# nrf7140_application register map
Vendor: Nordic Semiconductor; Series: nRF71; File version: 1
CPU: CM33 r0p4, little endian, MPU, FPU, 3 interrupt priority bits, 480 interrupts, 8 SAU regions
Registers are 32-bit, read-write, reset 0x0 unless marked. A register's access mark holds for its fields unless they carry their own. Offsets are from the block's base; [hi:lo] are bit positions; lines under a group give offsets from that group; {n}, {i} and the like mark numbered series; 'fields as' and 'values as' point back to an identical list.

## GLOBAL_DISPC_NS (part 3 of 3) — DISPC
Base 0x49004000
0x1000 CORE group — Unspecified
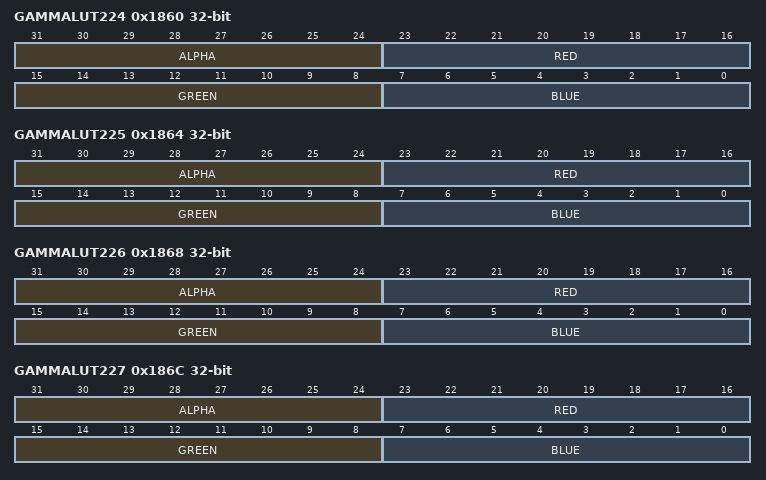
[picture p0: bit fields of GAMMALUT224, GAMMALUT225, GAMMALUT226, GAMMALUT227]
  0x1860 GAMMALUT224 — Layer 2 palette/gamma correction memory region.
    [31:24] ALPHA wo — Color alpha is used as Lut color.
    [23:16] RED wo — Color red is used as Lut color.
    [15:8] GREEN wo — Color green is used as Lut color.
    [7:0] BLUE wo — Color blue is used as Lut color.
  0x1864 GAMMALUT225 — Layer 2 palette/gamma correction memory region.
    fields as CORE.GAMMALUT224
  0x1868 GAMMALUT226 — Layer 2 palette/gamma correction memory region.
    fields as CORE.GAMMALUT224
  0x186C GAMMALUT227 — Layer 2 palette/gamma correction memory region.
    fields as CORE.GAMMALUT224
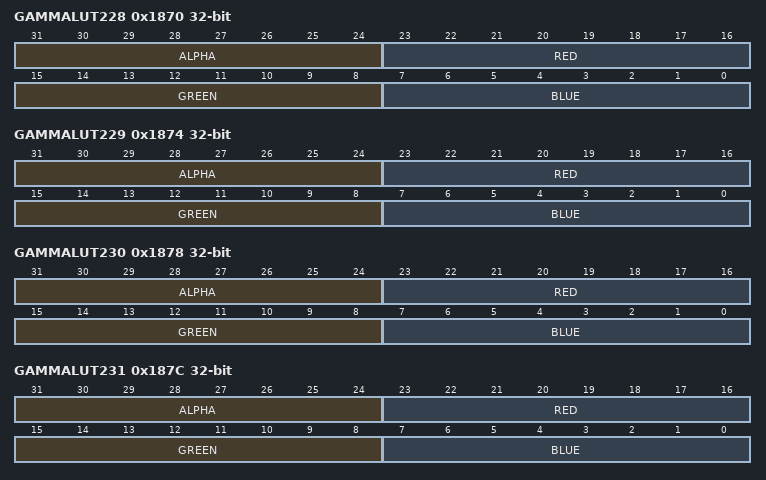
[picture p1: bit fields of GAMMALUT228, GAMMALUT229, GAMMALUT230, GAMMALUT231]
  0x1870 GAMMALUT228 — Layer 2 palette/gamma correction memory region.
    fields as CORE.GAMMALUT224
  0x1874 GAMMALUT229 — Layer 2 palette/gamma correction memory region.
    fields as CORE.GAMMALUT224
  0x1878 GAMMALUT230 — Layer 2 palette/gamma correction memory region.
    fields as CORE.GAMMALUT224
  0x187C GAMMALUT231 — Layer 2 palette/gamma correction memory region.
    fields as CORE.GAMMALUT224
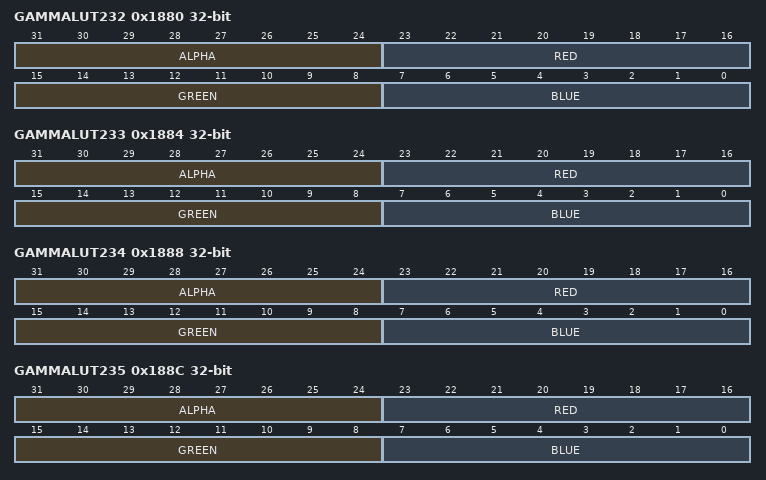
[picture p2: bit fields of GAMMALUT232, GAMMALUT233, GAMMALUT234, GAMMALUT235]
  0x1880 GAMMALUT232 — Layer 2 palette/gamma correction memory region.
    fields as CORE.GAMMALUT224
  0x1884 GAMMALUT233 — Layer 2 palette/gamma correction memory region.
    fields as CORE.GAMMALUT224
  0x1888 GAMMALUT234 — Layer 2 palette/gamma correction memory region.
    fields as CORE.GAMMALUT224
  0x188C GAMMALUT235 — Layer 2 palette/gamma correction memory region.
    fields as CORE.GAMMALUT224
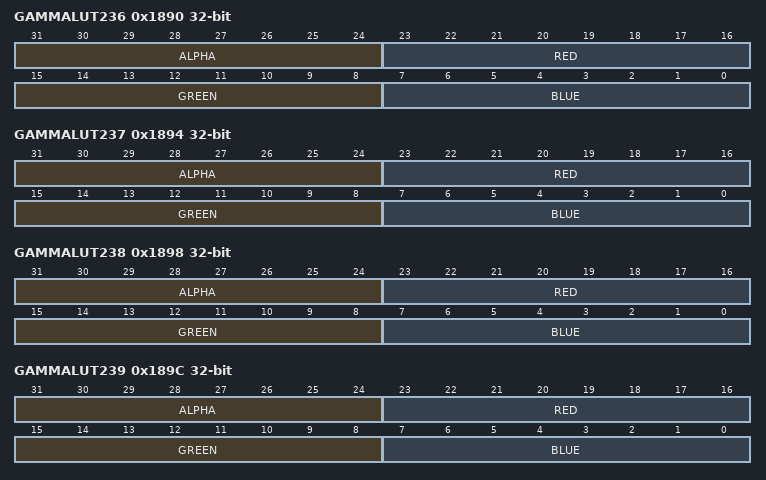
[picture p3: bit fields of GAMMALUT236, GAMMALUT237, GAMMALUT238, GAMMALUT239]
  0x1890 GAMMALUT236 — Layer 2 palette/gamma correction memory region.
    fields as CORE.GAMMALUT224
  0x1894 GAMMALUT237 — Layer 2 palette/gamma correction memory region.
    fields as CORE.GAMMALUT224
  0x1898 GAMMALUT238 — Layer 2 palette/gamma correction memory region.
    fields as CORE.GAMMALUT224
  0x189C GAMMALUT239 — Layer 2 palette/gamma correction memory region.
    fields as CORE.GAMMALUT224
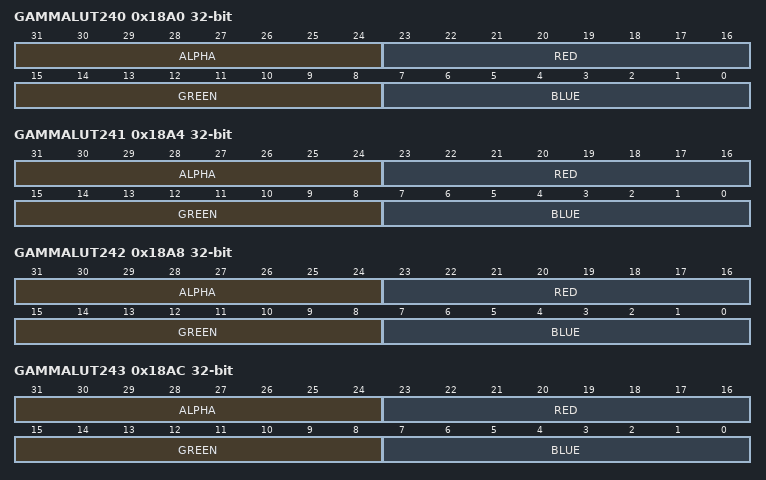
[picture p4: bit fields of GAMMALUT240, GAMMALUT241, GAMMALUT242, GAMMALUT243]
  0x18A0 GAMMALUT240 — Layer 2 palette/gamma correction memory region.
    fields as CORE.GAMMALUT224
  0x18A4 GAMMALUT241 — Layer 2 palette/gamma correction memory region.
    fields as CORE.GAMMALUT224
  0x18A8 GAMMALUT242 — Layer 2 palette/gamma correction memory region.
    fields as CORE.GAMMALUT224
  0x18AC GAMMALUT243 — Layer 2 palette/gamma correction memory region.
    fields as CORE.GAMMALUT224
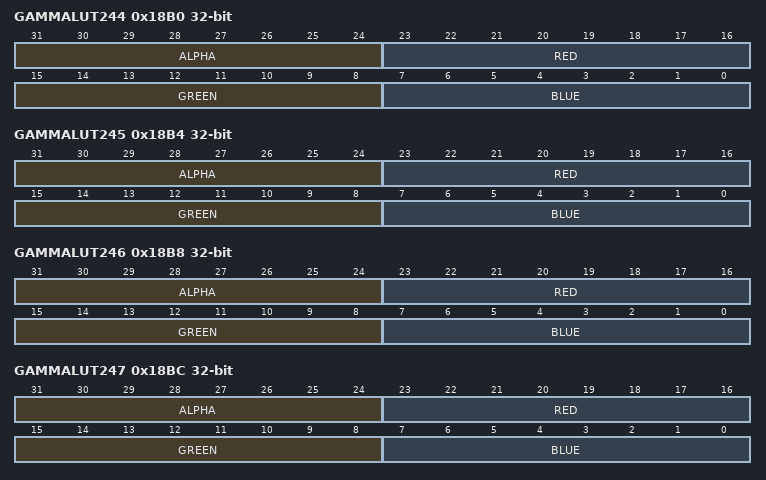
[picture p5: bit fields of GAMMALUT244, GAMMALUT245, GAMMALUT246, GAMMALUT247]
  0x18B0 GAMMALUT244 — Layer 2 palette/gamma correction memory region.
    fields as CORE.GAMMALUT224
  0x18B4 GAMMALUT245 — Layer 2 palette/gamma correction memory region.
    fields as CORE.GAMMALUT224
  0x18B8 GAMMALUT246 — Layer 2 palette/gamma correction memory region.
    fields as CORE.GAMMALUT224
  0x18BC GAMMALUT247 — Layer 2 palette/gamma correction memory region.
    fields as CORE.GAMMALUT224
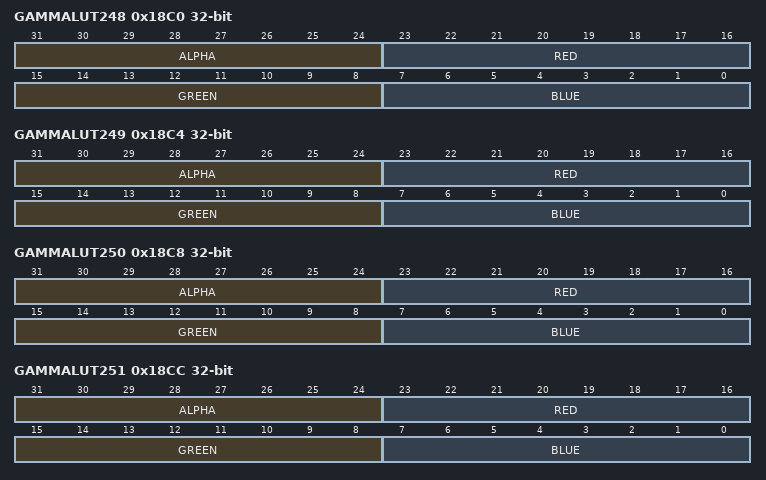
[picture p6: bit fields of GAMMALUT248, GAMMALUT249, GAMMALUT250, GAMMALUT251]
  0x18C0 GAMMALUT248 — Layer 2 palette/gamma correction memory region.
    fields as CORE.GAMMALUT224
  0x18C4 GAMMALUT249 — Layer 2 palette/gamma correction memory region.
    fields as CORE.GAMMALUT224
  0x18C8 GAMMALUT250 — Layer 2 palette/gamma correction memory region.
    fields as CORE.GAMMALUT224
  0x18CC GAMMALUT251 — Layer 2 palette/gamma correction memory region.
    fields as CORE.GAMMALUT224
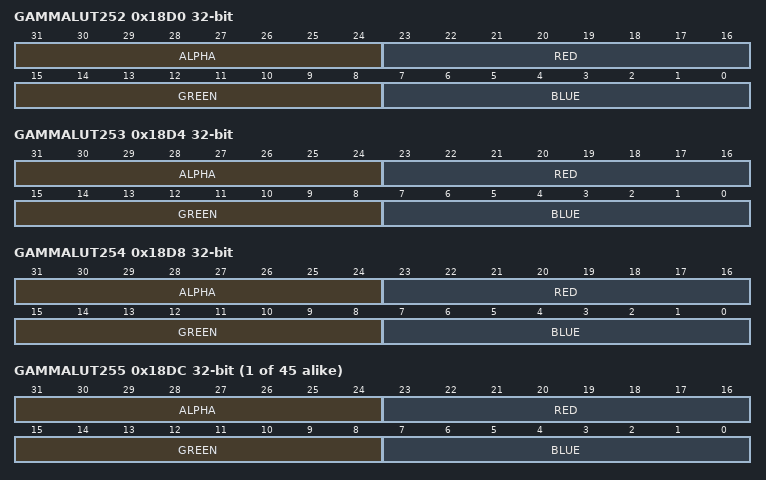
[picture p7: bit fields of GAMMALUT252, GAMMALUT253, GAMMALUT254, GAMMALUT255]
  0x18D0 GAMMALUT252 — Layer 2 palette/gamma correction memory region.
    fields as CORE.GAMMALUT224
  0x18D4 GAMMALUT253 — Layer 2 palette/gamma correction memory region.
    fields as CORE.GAMMALUT224
  0x18D8 GAMMALUT254 — Layer 2 palette/gamma correction memory region.
    fields as CORE.GAMMALUT224
  {0x14E0+4j} GAMMALUT{j} (j=255..299) — Layer 2 palette/gamma correction memory region.
    fields as CORE.GAMMALUT224
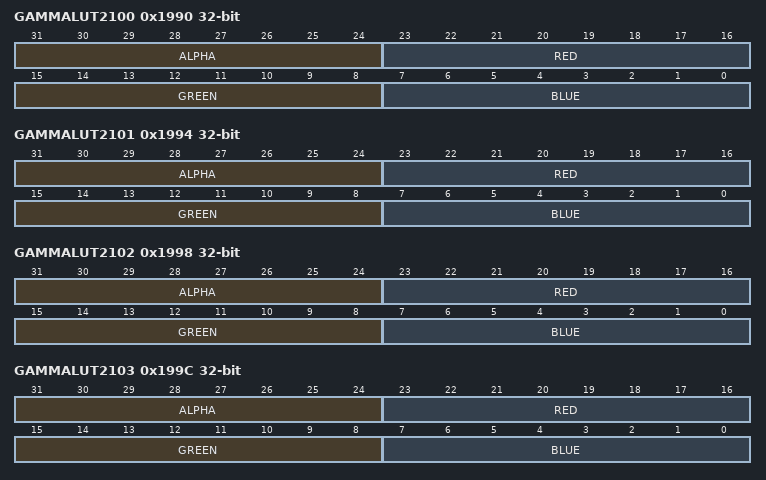
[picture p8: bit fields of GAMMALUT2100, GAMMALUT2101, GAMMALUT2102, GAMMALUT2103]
  0x1990 GAMMALUT2100 — Layer 2 palette/gamma correction memory region.
    fields as CORE.GAMMALUT224
  0x1994 GAMMALUT2101 — Layer 2 palette/gamma correction memory region.
    fields as CORE.GAMMALUT224
  0x1998 GAMMALUT2102 — Layer 2 palette/gamma correction memory region.
    fields as CORE.GAMMALUT224
  0x199C GAMMALUT2103 — Layer 2 palette/gamma correction memory region.
    fields as CORE.GAMMALUT224
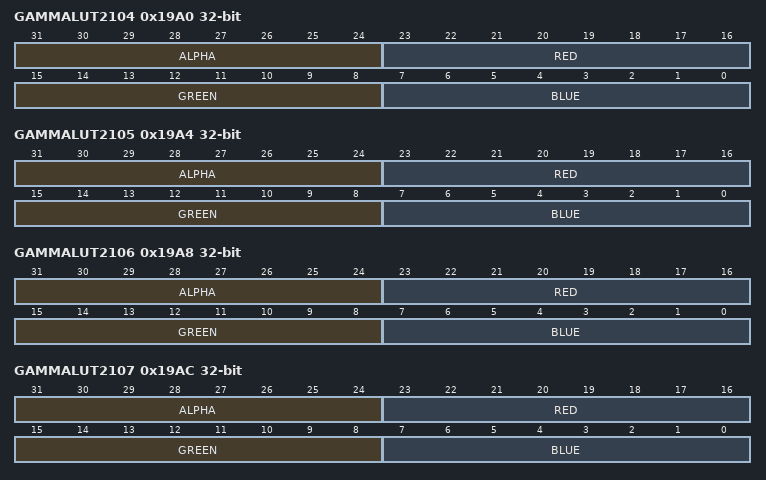
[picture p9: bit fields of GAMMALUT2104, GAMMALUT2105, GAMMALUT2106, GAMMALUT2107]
  0x19A0 GAMMALUT2104 — Layer 2 palette/gamma correction memory region.
    fields as CORE.GAMMALUT224
  0x19A4 GAMMALUT2105 — Layer 2 palette/gamma correction memory region.
    fields as CORE.GAMMALUT224
  0x19A8 GAMMALUT2106 — Layer 2 palette/gamma correction memory region.
    fields as CORE.GAMMALUT224
  0x19AC GAMMALUT2107 — Layer 2 palette/gamma correction memory region.
    fields as CORE.GAMMALUT224
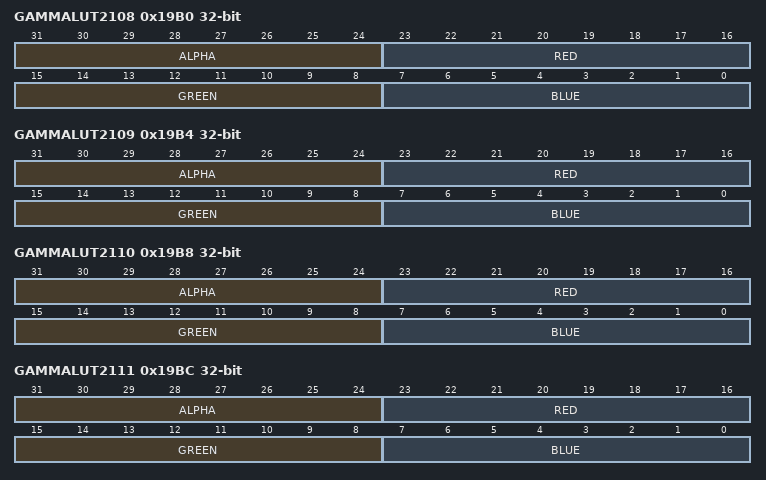
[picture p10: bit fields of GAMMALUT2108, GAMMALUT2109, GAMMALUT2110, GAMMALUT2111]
  0x19B0 GAMMALUT2108 — Layer 2 palette/gamma correction memory region.
    fields as CORE.GAMMALUT224
  0x19B4 GAMMALUT2109 — Layer 2 palette/gamma correction memory region.
    fields as CORE.GAMMALUT224
  0x19B8 GAMMALUT2110 — Layer 2 palette/gamma correction memory region.
    fields as CORE.GAMMALUT224
  0x19BC GAMMALUT2111 — Layer 2 palette/gamma correction memory region.
    fields as CORE.GAMMALUT224
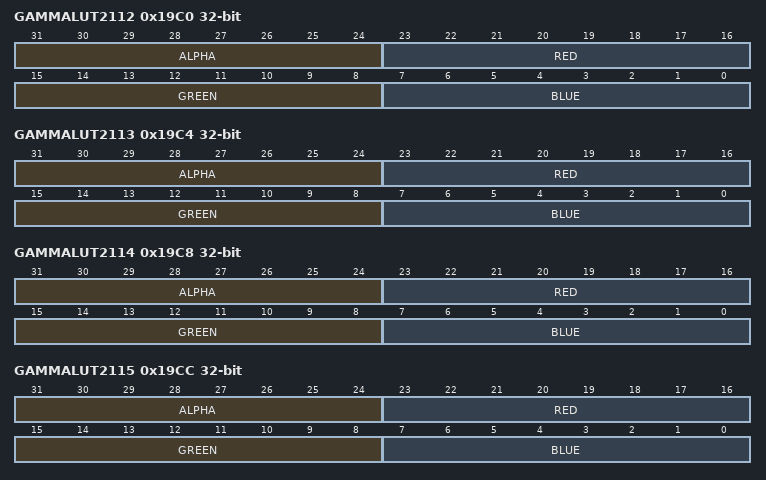
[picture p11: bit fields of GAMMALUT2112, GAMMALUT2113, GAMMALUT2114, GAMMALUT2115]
  0x19C0 GAMMALUT2112 — Layer 2 palette/gamma correction memory region.
    fields as CORE.GAMMALUT224
  0x19C4 GAMMALUT2113 — Layer 2 palette/gamma correction memory region.
    fields as CORE.GAMMALUT224
  0x19C8 GAMMALUT2114 — Layer 2 palette/gamma correction memory region.
    fields as CORE.GAMMALUT224
  0x19CC GAMMALUT2115 — Layer 2 palette/gamma correction memory region.
    fields as CORE.GAMMALUT224
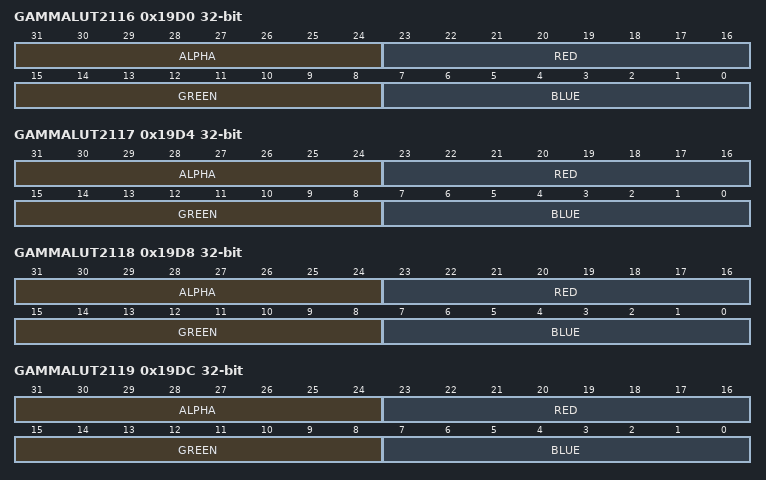
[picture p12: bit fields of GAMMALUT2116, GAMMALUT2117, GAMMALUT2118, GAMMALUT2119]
  0x19D0 GAMMALUT2116 — Layer 2 palette/gamma correction memory region.
    fields as CORE.GAMMALUT224
  0x19D4 GAMMALUT2117 — Layer 2 palette/gamma correction memory region.
    fields as CORE.GAMMALUT224
  0x19D8 GAMMALUT2118 — Layer 2 palette/gamma correction memory region.
    fields as CORE.GAMMALUT224
  0x19DC GAMMALUT2119 — Layer 2 palette/gamma correction memory region.
    fields as CORE.GAMMALUT224
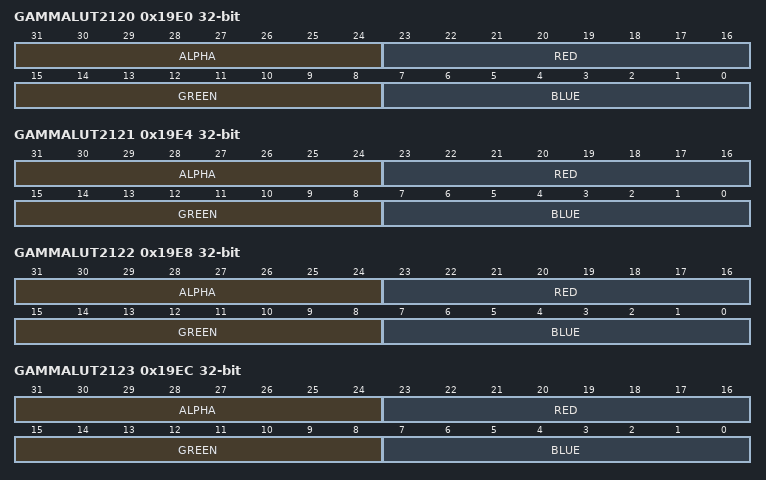
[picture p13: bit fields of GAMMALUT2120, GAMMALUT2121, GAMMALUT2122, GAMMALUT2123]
  0x19E0 GAMMALUT2120 — Layer 2 palette/gamma correction memory region.
    fields as CORE.GAMMALUT224
  0x19E4 GAMMALUT2121 — Layer 2 palette/gamma correction memory region.
    fields as CORE.GAMMALUT224
  0x19E8 GAMMALUT2122 — Layer 2 palette/gamma correction memory region.
    fields as CORE.GAMMALUT224
  0x19EC GAMMALUT2123 — Layer 2 palette/gamma correction memory region.
    fields as CORE.GAMMALUT224
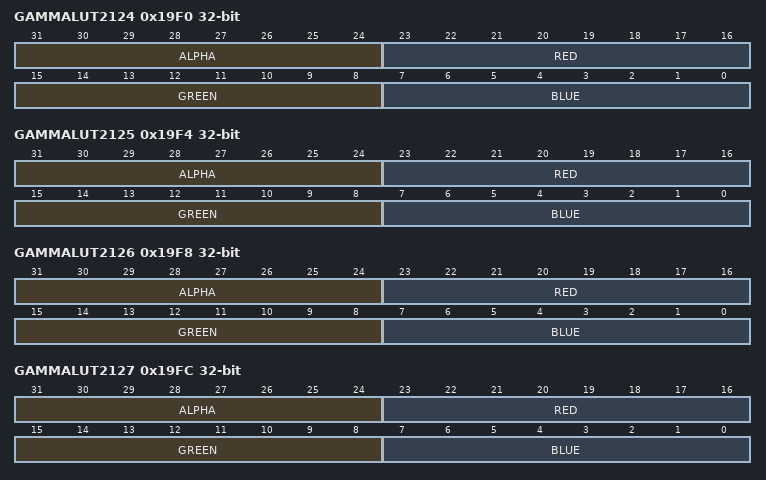
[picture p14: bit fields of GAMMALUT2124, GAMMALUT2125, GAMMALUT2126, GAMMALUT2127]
  0x19F0 GAMMALUT2124 — Layer 2 palette/gamma correction memory region.
    fields as CORE.GAMMALUT224
  0x19F4 GAMMALUT2125 — Layer 2 palette/gamma correction memory region.
    fields as CORE.GAMMALUT224
  0x19F8 GAMMALUT2126 — Layer 2 palette/gamma correction memory region.
    fields as CORE.GAMMALUT224
  0x19FC GAMMALUT2127 — Layer 2 palette/gamma correction memory region.
    fields as CORE.GAMMALUT224
  0x1A00 GAMMALUT2128 — Layer 2 palette/gamma correction memory region.
    fields as CORE.GAMMALUT224
  0x1A04 GAMMALUT2129 — Layer 2 palette/gamma correction memory region.
    fields as CORE.GAMMALUT224
  0x1A08 GAMMALUT2130 — Layer 2 palette/gamma correction memory region.
    fields as CORE.GAMMALUT224
  0x1A0C GAMMALUT2131 — Layer 2 palette/gamma correction memory region.
    fields as CORE.GAMMALUT224
  0x1A10 GAMMALUT2132 — Layer 2 palette/gamma correction memory region.
    fields as CORE.GAMMALUT224
  0x1A14 GAMMALUT2133 — Layer 2 palette/gamma correction memory region.
    fields as CORE.GAMMALUT224
  0x1A18 GAMMALUT2134 — Layer 2 palette/gamma correction memory region.
    fields as CORE.GAMMALUT224
  0x1A1C GAMMALUT2135 — Layer 2 palette/gamma correction memory region.
    fields as CORE.GAMMALUT224
  0x1A20 GAMMALUT2136 — Layer 2 palette/gamma correction memory region.
    fields as CORE.GAMMALUT224
  0x1A24 GAMMALUT2137 — Layer 2 palette/gamma correction memory region.
    fields as CORE.GAMMALUT224
  0x1A28 GAMMALUT2138 — Layer 2 palette/gamma correction memory region.
    fields as CORE.GAMMALUT224
  0x1A2C GAMMALUT2139 — Layer 2 palette/gamma correction memory region.
    fields as CORE.GAMMALUT224
  0x1A30 GAMMALUT2140 — Layer 2 palette/gamma correction memory region.
    fields as CORE.GAMMALUT224
  0x1A34 GAMMALUT2141 — Layer 2 palette/gamma correction memory region.
    fields as CORE.GAMMALUT224
  0x1A38 GAMMALUT2142 — Layer 2 palette/gamma correction memory region.
    fields as CORE.GAMMALUT224
  0x1A3C GAMMALUT2143 — Layer 2 palette/gamma correction memory region.
    fields as CORE.GAMMALUT224
  0x1A40 GAMMALUT2144 — Layer 2 palette/gamma correction memory region.
    fields as CORE.GAMMALUT224
  0x1A44 GAMMALUT2145 — Layer 2 palette/gamma correction memory region.
    fields as CORE.GAMMALUT224
  0x1A48 GAMMALUT2146 — Layer 2 palette/gamma correction memory region.
    fields as CORE.GAMMALUT224
  0x1A4C GAMMALUT2147 — Layer 2 palette/gamma correction memory region.
    fields as CORE.GAMMALUT224
  0x1A50 GAMMALUT2148 — Layer 2 palette/gamma correction memory region.
    fields as CORE.GAMMALUT224
  0x1A54 GAMMALUT2149 — Layer 2 palette/gamma correction memory region.
    fields as CORE.GAMMALUT224
  0x1A58 GAMMALUT2150 — Layer 2 palette/gamma correction memory region.
    fields as CORE.GAMMALUT224
  0x1A5C GAMMALUT2151 — Layer 2 palette/gamma correction memory region.
    fields as CORE.GAMMALUT224
  0x1A60 GAMMALUT2152 — Layer 2 palette/gamma correction memory region.
    fields as CORE.GAMMALUT224
  0x1A64 GAMMALUT2153 — Layer 2 palette/gamma correction memory region.
    fields as CORE.GAMMALUT224
  0x1A68 GAMMALUT2154 — Layer 2 palette/gamma correction memory region.
    fields as CORE.GAMMALUT224
  0x1A6C GAMMALUT2155 — Layer 2 palette/gamma correction memory region.
    fields as CORE.GAMMALUT224
  0x1A70 GAMMALUT2156 — Layer 2 palette/gamma correction memory region.
    fields as CORE.GAMMALUT224
  0x1A74 GAMMALUT2157 — Layer 2 palette/gamma correction memory region.
    fields as CORE.GAMMALUT224
  0x1A78 GAMMALUT2158 — Layer 2 palette/gamma correction memory region.
    fields as CORE.GAMMALUT224
  0x1A7C GAMMALUT2159 — Layer 2 palette/gamma correction memory region.
    fields as CORE.GAMMALUT224
  0x1A80 GAMMALUT2160 — Layer 2 palette/gamma correction memory region.
    fields as CORE.GAMMALUT224
  0x1A84 GAMMALUT2161 — Layer 2 palette/gamma correction memory region.
    fields as CORE.GAMMALUT224
  0x1A88 GAMMALUT2162 — Layer 2 palette/gamma correction memory region.
    fields as CORE.GAMMALUT224
  0x1A8C GAMMALUT2163 — Layer 2 palette/gamma correction memory region.
    fields as CORE.GAMMALUT224
  0x1A90 GAMMALUT2164 — Layer 2 palette/gamma correction memory region.
    fields as CORE.GAMMALUT224
  0x1A94 GAMMALUT2165 — Layer 2 palette/gamma correction memory region.
    fields as CORE.GAMMALUT224
  0x1A98 GAMMALUT2166 — Layer 2 palette/gamma correction memory region.
    fields as CORE.GAMMALUT224
  0x1A9C GAMMALUT2167 — Layer 2 palette/gamma correction memory region.
    fields as CORE.GAMMALUT224
  0x1AA0 GAMMALUT2168 — Layer 2 palette/gamma correction memory region.
    fields as CORE.GAMMALUT224
  0x1AA4 GAMMALUT2169 — Layer 2 palette/gamma correction memory region.
    fields as CORE.GAMMALUT224
  0x1AA8 GAMMALUT2170 — Layer 2 palette/gamma correction memory region.
    fields as CORE.GAMMALUT224
  0x1AAC GAMMALUT2171 — Layer 2 palette/gamma correction memory region.
    fields as CORE.GAMMALUT224
  0x1AB0 GAMMALUT2172 — Layer 2 palette/gamma correction memory region.
    fields as CORE.GAMMALUT224
  0x1AB4 GAMMALUT2173 — Layer 2 palette/gamma correction memory region.
    fields as CORE.GAMMALUT224
  0x1AB8 GAMMALUT2174 — Layer 2 palette/gamma correction memory region.
    fields as CORE.GAMMALUT224
  0x1ABC GAMMALUT2175 — Layer 2 palette/gamma correction memory region.
    fields as CORE.GAMMALUT224
  0x1AC0 GAMMALUT2176 — Layer 2 palette/gamma correction memory region.
    fields as CORE.GAMMALUT224
  0x1AC4 GAMMALUT2177 — Layer 2 palette/gamma correction memory region.
    fields as CORE.GAMMALUT224
  0x1AC8 GAMMALUT2178 — Layer 2 palette/gamma correction memory region.
    fields as CORE.GAMMALUT224
  0x1ACC GAMMALUT2179 — Layer 2 palette/gamma correction memory region.
    fields as CORE.GAMMALUT224
  0x1AD0 GAMMALUT2180 — Layer 2 palette/gamma correction memory region.
    fields as CORE.GAMMALUT224
  0x1AD4 GAMMALUT2181 — Layer 2 palette/gamma correction memory region.
    fields as CORE.GAMMALUT224
  0x1AD8 GAMMALUT2182 — Layer 2 palette/gamma correction memory region.
    fields as CORE.GAMMALUT224
  0x1ADC GAMMALUT2183 — Layer 2 palette/gamma correction memory region.
    fields as CORE.GAMMALUT224
  0x1AE0 GAMMALUT2184 — Layer 2 palette/gamma correction memory region.
    fields as CORE.GAMMALUT224
  0x1AE4 GAMMALUT2185 — Layer 2 palette/gamma correction memory region.
    fields as CORE.GAMMALUT224
  0x1AE8 GAMMALUT2186 — Layer 2 palette/gamma correction memory region.
    fields as CORE.GAMMALUT224
  0x1AEC GAMMALUT2187 — Layer 2 palette/gamma correction memory region.
    fields as CORE.GAMMALUT224
  0x1AF0 GAMMALUT2188 — Layer 2 palette/gamma correction memory region.
    fields as CORE.GAMMALUT224
  0x1AF4 GAMMALUT2189 — Layer 2 palette/gamma correction memory region.
    fields as CORE.GAMMALUT224
  0x1AF8 GAMMALUT2190 — Layer 2 palette/gamma correction memory region.
    fields as CORE.GAMMALUT224
  0x1AFC GAMMALUT2191 — Layer 2 palette/gamma correction memory region.
    fields as CORE.GAMMALUT224
  0x1B00 GAMMALUT2192 — Layer 2 palette/gamma correction memory region.
    fields as CORE.GAMMALUT224
  0x1B04 GAMMALUT2193 — Layer 2 palette/gamma correction memory region.
    fields as CORE.GAMMALUT224
  0x1B08 GAMMALUT2194 — Layer 2 palette/gamma correction memory region.
    fields as CORE.GAMMALUT224
  0x1B0C GAMMALUT2195 — Layer 2 palette/gamma correction memory region.
    fields as CORE.GAMMALUT224
  0x1B10 GAMMALUT2196 — Layer 2 palette/gamma correction memory region.
    fields as CORE.GAMMALUT224
  0x1B14 GAMMALUT2197 — Layer 2 palette/gamma correction memory region.
    fields as CORE.GAMMALUT224
  0x1B18 GAMMALUT2198 — Layer 2 palette/gamma correction memory region.
    fields as CORE.GAMMALUT224
  0x1B1C GAMMALUT2199 — Layer 2 palette/gamma correction memory region.
    fields as CORE.GAMMALUT224
  0x1B20 GAMMALUT2200 — Layer 2 palette/gamma correction memory region.
    fields as CORE.GAMMALUT224
  0x1B24 GAMMALUT2201 — Layer 2 palette/gamma correction memory region.
    fields as CORE.GAMMALUT224
  0x1B28 GAMMALUT2202 — Layer 2 palette/gamma correction memory region.
    fields as CORE.GAMMALUT224
  0x1B2C GAMMALUT2203 — Layer 2 palette/gamma correction memory region.
    fields as CORE.GAMMALUT224
  0x1B30 GAMMALUT2204 — Layer 2 palette/gamma correction memory region.
    fields as CORE.GAMMALUT224
  0x1B34 GAMMALUT2205 — Layer 2 palette/gamma correction memory region.
    fields as CORE.GAMMALUT224
  0x1B38 GAMMALUT2206 — Layer 2 palette/gamma correction memory region.
    fields as CORE.GAMMALUT224
  0x1B3C GAMMALUT2207 — Layer 2 palette/gamma correction memory region.
    fields as CORE.GAMMALUT224
  0x1B40 GAMMALUT2208 — Layer 2 palette/gamma correction memory region.
    fields as CORE.GAMMALUT224
  0x1B44 GAMMALUT2209 — Layer 2 palette/gamma correction memory region.
    fields as CORE.GAMMALUT224
  0x1B48 GAMMALUT2210 — Layer 2 palette/gamma correction memory region.
    fields as CORE.GAMMALUT224
  0x1B4C GAMMALUT2211 — Layer 2 palette/gamma correction memory region.
    fields as CORE.GAMMALUT224
  0x1B50 GAMMALUT2212 — Layer 2 palette/gamma correction memory region.
    fields as CORE.GAMMALUT224
  0x1B54 GAMMALUT2213 — Layer 2 palette/gamma correction memory region.
    fields as CORE.GAMMALUT224
  0x1B58 GAMMALUT2214 — Layer 2 palette/gamma correction memory region.
    fields as CORE.GAMMALUT224
  0x1B5C GAMMALUT2215 — Layer 2 palette/gamma correction memory region.
    fields as CORE.GAMMALUT224
  0x1B60 GAMMALUT2216 — Layer 2 palette/gamma correction memory region.
    fields as CORE.GAMMALUT224
  0x1B64 GAMMALUT2217 — Layer 2 palette/gamma correction memory region.
    fields as CORE.GAMMALUT224
  0x1B68 GAMMALUT2218 — Layer 2 palette/gamma correction memory region.
    fields as CORE.GAMMALUT224
  0x1B6C GAMMALUT2219 — Layer 2 palette/gamma correction memory region.
    fields as CORE.GAMMALUT224
  0x1B70 GAMMALUT2220 — Layer 2 palette/gamma correction memory region.
    fields as CORE.GAMMALUT224
  0x1B74 GAMMALUT2221 — Layer 2 palette/gamma correction memory region.
    fields as CORE.GAMMALUT224
  0x1B78 GAMMALUT2222 — Layer 2 palette/gamma correction memory region.
    fields as CORE.GAMMALUT224
  0x1B7C GAMMALUT2223 — Layer 2 palette/gamma correction memory region.
    fields as CORE.GAMMALUT224
  0x1B80 GAMMALUT2224 — Layer 2 palette/gamma correction memory region.
    fields as CORE.GAMMALUT224
  0x1B84 GAMMALUT2225 — Layer 2 palette/gamma correction memory region.
    fields as CORE.GAMMALUT224
  0x1B88 GAMMALUT2226 — Layer 2 palette/gamma correction memory region.
    fields as CORE.GAMMALUT224
  0x1B8C GAMMALUT2227 — Layer 2 palette/gamma correction memory region.
    fields as CORE.GAMMALUT224
  0x1B90 GAMMALUT2228 — Layer 2 palette/gamma correction memory region.
    fields as CORE.GAMMALUT224
  0x1B94 GAMMALUT2229 — Layer 2 palette/gamma correction memory region.
    fields as CORE.GAMMALUT224
  0x1B98 GAMMALUT2230 — Layer 2 palette/gamma correction memory region.
    fields as CORE.GAMMALUT224
  0x1B9C GAMMALUT2231 — Layer 2 palette/gamma correction memory region.
    fields as CORE.GAMMALUT224
  0x1BA0 GAMMALUT2232 — Layer 2 palette/gamma correction memory region.
    fields as CORE.GAMMALUT224
  0x1BA4 GAMMALUT2233 — Layer 2 palette/gamma correction memory region.
    fields as CORE.GAMMALUT224
  0x1BA8 GAMMALUT2234 — Layer 2 palette/gamma correction memory region.
    fields as CORE.GAMMALUT224
  0x1BAC GAMMALUT2235 — Layer 2 palette/gamma correction memory region.
    fields as CORE.GAMMALUT224
  0x1BB0 GAMMALUT2236 — Layer 2 palette/gamma correction memory region.
    fields as CORE.GAMMALUT224
  0x1BB4 GAMMALUT2237 — Layer 2 palette/gamma correction memory region.
    fields as CORE.GAMMALUT224
  0x1BB8 GAMMALUT2238 — Layer 2 palette/gamma correction memory region.
    fields as CORE.GAMMALUT224
  0x1BBC GAMMALUT2239 — Layer 2 palette/gamma correction memory region.
    fields as CORE.GAMMALUT224
  0x1BC0 GAMMALUT2240 — Layer 2 palette/gamma correction memory region.
    fields as CORE.GAMMALUT224
  0x1BC4 GAMMALUT2241 — Layer 2 palette/gamma correction memory region.
    fields as CORE.GAMMALUT224
  0x1BC8 GAMMALUT2242 — Layer 2 palette/gamma correction memory region.
    fields as CORE.GAMMALUT224
  0x1BCC GAMMALUT2243 — Layer 2 palette/gamma correction memory region.
    fields as CORE.GAMMALUT224
  0x1BD0 GAMMALUT2244 — Layer 2 palette/gamma correction memory region.
    fields as CORE.GAMMALUT224
  0x1BD4 GAMMALUT2245 — Layer 2 palette/gamma correction memory region.
    fields as CORE.GAMMALUT224
  0x1BD8 GAMMALUT2246 — Layer 2 palette/gamma correction memory region.
    fields as CORE.GAMMALUT224
  0x1BDC GAMMALUT2247 — Layer 2 palette/gamma correction memory region.
    fields as CORE.GAMMALUT224
  0x1BE0 GAMMALUT2248 — Layer 2 palette/gamma correction memory region.
    fields as CORE.GAMMALUT224
  0x1BE4 GAMMALUT2249 — Layer 2 palette/gamma correction memory region.
    fields as CORE.GAMMALUT224
  0x1BE8 GAMMALUT2250 — Layer 2 palette/gamma correction memory region.
    fields as CORE.GAMMALUT224
  0x1BEC GAMMALUT2251 — Layer 2 palette/gamma correction memory region.
    fields as CORE.GAMMALUT224
  0x1BF0 GAMMALUT2252 — Layer 2 palette/gamma correction memory region.
    fields as CORE.GAMMALUT224
  0x1BF4 GAMMALUT2253 — Layer 2 palette/gamma correction memory region.
    fields as CORE.GAMMALUT224
  0x1BF8 GAMMALUT2254 — Layer 2 palette/gamma correction memory region.
    fields as CORE.GAMMALUT224
  0x1BFC GAMMALUT2255 — Layer 2 palette/gamma correction memory region.
    fields as CORE.GAMMALUT224
  0x1C00 GAMMALUT30 — Layer 3 palette/gamma correction memory region.
    fields as CORE.GAMMALUT224
  0x1C04 GAMMALUT31 — Layer 3 palette/gamma correction memory region.
    fields as CORE.GAMMALUT224
  0x1C08 GAMMALUT32 — Layer 3 palette/gamma correction memory region.
    fields as CORE.GAMMALUT224
  0x1C0C GAMMALUT33 — Layer 3 palette/gamma correction memory region.
    fields as CORE.GAMMALUT224
  0x1C10 GAMMALUT34 — Layer 3 palette/gamma correction memory region.
    fields as CORE.GAMMALUT224
  0x1C14 GAMMALUT35 — Layer 3 palette/gamma correction memory region.
    fields as CORE.GAMMALUT224
  0x1C18 GAMMALUT36 — Layer 3 palette/gamma correction memory region.
    fields as CORE.GAMMALUT224
  0x1C1C GAMMALUT37 — Layer 3 palette/gamma correction memory region.
    fields as CORE.GAMMALUT224
  0x1C20 GAMMALUT38 — Layer 3 palette/gamma correction memory region.
    fields as CORE.GAMMALUT224
  0x1C24 GAMMALUT39 — Layer 3 palette/gamma correction memory region.
    fields as CORE.GAMMALUT224
  {0x1750+4j} GAMMALUT{j} (j=310..399) — Layer 3 palette/gamma correction memory region.
    fields as CORE.GAMMALUT224
  0x1D90 GAMMALUT3100 — Layer 3 palette/gamma correction memory region.
    fields as CORE.GAMMALUT224
  0x1D94 GAMMALUT3101 — Layer 3 palette/gamma correction memory region.
    fields as CORE.GAMMALUT224
  0x1D98 GAMMALUT3102 — Layer 3 palette/gamma correction memory region.
    fields as CORE.GAMMALUT224
  0x1D9C GAMMALUT3103 — Layer 3 palette/gamma correction memory region.
    fields as CORE.GAMMALUT224
  0x1DA0 GAMMALUT3104 — Layer 3 palette/gamma correction memory region.
    fields as CORE.GAMMALUT224
  0x1DA4 GAMMALUT3105 — Layer 3 palette/gamma correction memory region.
    fields as CORE.GAMMALUT224
  0x1DA8 GAMMALUT3106 — Layer 3 palette/gamma correction memory region.
    fields as CORE.GAMMALUT224
  0x1DAC GAMMALUT3107 — Layer 3 palette/gamma correction memory region.
    fields as CORE.GAMMALUT224
  0x1DB0 GAMMALUT3108 — Layer 3 palette/gamma correction memory region.
    fields as CORE.GAMMALUT224
  0x1DB4 GAMMALUT3109 — Layer 3 palette/gamma correction memory region.
    fields as CORE.GAMMALUT224
  0x1DB8 GAMMALUT3110 — Layer 3 palette/gamma correction memory region.
    fields as CORE.GAMMALUT224
  0x1DBC GAMMALUT3111 — Layer 3 palette/gamma correction memory region.
    fields as CORE.GAMMALUT224
  0x1DC0 GAMMALUT3112 — Layer 3 palette/gamma correction memory region.
    fields as CORE.GAMMALUT224
  0x1DC4 GAMMALUT3113 — Layer 3 palette/gamma correction memory region.
    fields as CORE.GAMMALUT224
  0x1DC8 GAMMALUT3114 — Layer 3 palette/gamma correction memory region.
    fields as CORE.GAMMALUT224
  0x1DCC GAMMALUT3115 — Layer 3 palette/gamma correction memory region.
    fields as CORE.GAMMALUT224
  0x1DD0 GAMMALUT3116 — Layer 3 palette/gamma correction memory region.
    fields as CORE.GAMMALUT224
  0x1DD4 GAMMALUT3117 — Layer 3 palette/gamma correction memory region.
    fields as CORE.GAMMALUT224
  0x1DD8 GAMMALUT3118 — Layer 3 palette/gamma correction memory region.
    fields as CORE.GAMMALUT224
  0x1DDC GAMMALUT3119 — Layer 3 palette/gamma correction memory region.
    fields as CORE.GAMMALUT224
  0x1DE0 GAMMALUT3120 — Layer 3 palette/gamma correction memory region.
    fields as CORE.GAMMALUT224
  0x1DE4 GAMMALUT3121 — Layer 3 palette/gamma correction memory region.
    fields as CORE.GAMMALUT224
  0x1DE8 GAMMALUT3122 — Layer 3 palette/gamma correction memory region.
    fields as CORE.GAMMALUT224
  0x1DEC GAMMALUT3123 — Layer 3 palette/gamma correction memory region.
    fields as CORE.GAMMALUT224
  0x1DF0 GAMMALUT3124 — Layer 3 palette/gamma correction memory region.
    fields as CORE.GAMMALUT224
  0x1DF4 GAMMALUT3125 — Layer 3 palette/gamma correction memory region.
    fields as CORE.GAMMALUT224
  0x1DF8 GAMMALUT3126 — Layer 3 palette/gamma correction memory region.
    fields as CORE.GAMMALUT224
  0x1DFC GAMMALUT3127 — Layer 3 palette/gamma correction memory region.
    fields as CORE.GAMMALUT224
  0x1E00 GAMMALUT3128 — Layer 3 palette/gamma correction memory region.
    fields as CORE.GAMMALUT224
  0x1E04 GAMMALUT3129 — Layer 3 palette/gamma correction memory region.
    fields as CORE.GAMMALUT224
  0x1E08 GAMMALUT3130 — Layer 3 palette/gamma correction memory region.
    fields as CORE.GAMMALUT224
  0x1E0C GAMMALUT3131 — Layer 3 palette/gamma correction memory region.
    fields as CORE.GAMMALUT224
  0x1E10 GAMMALUT3132 — Layer 3 palette/gamma correction memory region.
    fields as CORE.GAMMALUT224
  0x1E14 GAMMALUT3133 — Layer 3 palette/gamma correction memory region.
    fields as CORE.GAMMALUT224
  0x1E18 GAMMALUT3134 — Layer 3 palette/gamma correction memory region.
    fields as CORE.GAMMALUT224
  0x1E1C GAMMALUT3135 — Layer 3 palette/gamma correction memory region.
    fields as CORE.GAMMALUT224
  0x1E20 GAMMALUT3136 — Layer 3 palette/gamma correction memory region.
    fields as CORE.GAMMALUT224
  0x1E24 GAMMALUT3137 — Layer 3 palette/gamma correction memory region.
    fields as CORE.GAMMALUT224
  0x1E28 GAMMALUT3138 — Layer 3 palette/gamma correction memory region.
    fields as CORE.GAMMALUT224
  0x1E2C GAMMALUT3139 — Layer 3 palette/gamma correction memory region.
    fields as CORE.GAMMALUT224
  0x1E30 GAMMALUT3140 — Layer 3 palette/gamma correction memory region.
    fields as CORE.GAMMALUT224
  0x1E34 GAMMALUT3141 — Layer 3 palette/gamma correction memory region.
    fields as CORE.GAMMALUT224
  0x1E38 GAMMALUT3142 — Layer 3 palette/gamma correction memory region.
    fields as CORE.GAMMALUT224
  0x1E3C GAMMALUT3143 — Layer 3 palette/gamma correction memory region.
    fields as CORE.GAMMALUT224
  0x1E40 GAMMALUT3144 — Layer 3 palette/gamma correction memory region.
    fields as CORE.GAMMALUT224
  0x1E44 GAMMALUT3145 — Layer 3 palette/gamma correction memory region.
    fields as CORE.GAMMALUT224
  0x1E48 GAMMALUT3146 — Layer 3 palette/gamma correction memory region.
    fields as CORE.GAMMALUT224
  0x1E4C GAMMALUT3147 — Layer 3 palette/gamma correction memory region.
    fields as CORE.GAMMALUT224
  0x1E50 GAMMALUT3148 — Layer 3 palette/gamma correction memory region.
    fields as CORE.GAMMALUT224
  0x1E54 GAMMALUT3149 — Layer 3 palette/gamma correction memory region.
    fields as CORE.GAMMALUT224
  0x1E58 GAMMALUT3150 — Layer 3 palette/gamma correction memory region.
    fields as CORE.GAMMALUT224
  0x1E5C GAMMALUT3151 — Layer 3 palette/gamma correction memory region.
    fields as CORE.GAMMALUT224
  0x1E60 GAMMALUT3152 — Layer 3 palette/gamma correction memory region.
    fields as CORE.GAMMALUT224
  0x1E64 GAMMALUT3153 — Layer 3 palette/gamma correction memory region.
    fields as CORE.GAMMALUT224
  0x1E68 GAMMALUT3154 — Layer 3 palette/gamma correction memory region.
    fields as CORE.GAMMALUT224
  0x1E6C GAMMALUT3155 — Layer 3 palette/gamma correction memory region.
    fields as CORE.GAMMALUT224
  0x1E70 GAMMALUT3156 — Layer 3 palette/gamma correction memory region.
    fields as CORE.GAMMALUT224
  0x1E74 GAMMALUT3157 — Layer 3 palette/gamma correction memory region.
    fields as CORE.GAMMALUT224
  0x1E78 GAMMALUT3158 — Layer 3 palette/gamma correction memory region.
    fields as CORE.GAMMALUT224
  0x1E7C GAMMALUT3159 — Layer 3 palette/gamma correction memory region.
    fields as CORE.GAMMALUT224
  0x1E80 GAMMALUT3160 — Layer 3 palette/gamma correction memory region.
    fields as CORE.GAMMALUT224
  0x1E84 GAMMALUT3161 — Layer 3 palette/gamma correction memory region.
    fields as CORE.GAMMALUT224
  0x1E88 GAMMALUT3162 — Layer 3 palette/gamma correction memory region.
    fields as CORE.GAMMALUT224
  0x1E8C GAMMALUT3163 — Layer 3 palette/gamma correction memory region.
    fields as CORE.GAMMALUT224
  0x1E90 GAMMALUT3164 — Layer 3 palette/gamma correction memory region.
    fields as CORE.GAMMALUT224
  0x1E94 GAMMALUT3165 — Layer 3 palette/gamma correction memory region.
    fields as CORE.GAMMALUT224
  0x1E98 GAMMALUT3166 — Layer 3 palette/gamma correction memory region.
    fields as CORE.GAMMALUT224
  0x1E9C GAMMALUT3167 — Layer 3 palette/gamma correction memory region.
    fields as CORE.GAMMALUT224
  0x1EA0 GAMMALUT3168 — Layer 3 palette/gamma correction memory region.
    fields as CORE.GAMMALUT224
  0x1EA4 GAMMALUT3169 — Layer 3 palette/gamma correction memory region.
    fields as CORE.GAMMALUT224
  0x1EA8 GAMMALUT3170 — Layer 3 palette/gamma correction memory region.
    fields as CORE.GAMMALUT224
  0x1EAC GAMMALUT3171 — Layer 3 palette/gamma correction memory region.
    fields as CORE.GAMMALUT224
  0x1EB0 GAMMALUT3172 — Layer 3 palette/gamma correction memory region.
    fields as CORE.GAMMALUT224
  0x1EB4 GAMMALUT3173 — Layer 3 palette/gamma correction memory region.
    fields as CORE.GAMMALUT224
  0x1EB8 GAMMALUT3174 — Layer 3 palette/gamma correction memory region.
    fields as CORE.GAMMALUT224
  0x1EBC GAMMALUT3175 — Layer 3 palette/gamma correction memory region.
    fields as CORE.GAMMALUT224
  0x1EC0 GAMMALUT3176 — Layer 3 palette/gamma correction memory region.
    fields as CORE.GAMMALUT224
  0x1EC4 GAMMALUT3177 — Layer 3 palette/gamma correction memory region.
    fields as CORE.GAMMALUT224
  0x1EC8 GAMMALUT3178 — Layer 3 palette/gamma correction memory region.
    fields as CORE.GAMMALUT224
  0x1ECC GAMMALUT3179 — Layer 3 palette/gamma correction memory region.
    fields as CORE.GAMMALUT224
  0x1ED0 GAMMALUT3180 — Layer 3 palette/gamma correction memory region.
    fields as CORE.GAMMALUT224
  0x1ED4 GAMMALUT3181 — Layer 3 palette/gamma correction memory region.
    fields as CORE.GAMMALUT224
  0x1ED8 GAMMALUT3182 — Layer 3 palette/gamma correction memory region.
    fields as CORE.GAMMALUT224
  0x1EDC GAMMALUT3183 — Layer 3 palette/gamma correction memory region.
    fields as CORE.GAMMALUT224
  0x1EE0 GAMMALUT3184 — Layer 3 palette/gamma correction memory region.
    fields as CORE.GAMMALUT224
  0x1EE4 GAMMALUT3185 — Layer 3 palette/gamma correction memory region.
    fields as CORE.GAMMALUT224
  0x1EE8 GAMMALUT3186 — Layer 3 palette/gamma correction memory region.
    fields as CORE.GAMMALUT224
  0x1EEC GAMMALUT3187 — Layer 3 palette/gamma correction memory region.
    fields as CORE.GAMMALUT224
  0x1EF0 GAMMALUT3188 — Layer 3 palette/gamma correction memory region.
    fields as CORE.GAMMALUT224
  0x1EF4 GAMMALUT3189 — Layer 3 palette/gamma correction memory region.
    fields as CORE.GAMMALUT224
  0x1EF8 GAMMALUT3190 — Layer 3 palette/gamma correction memory region.
    fields as CORE.GAMMALUT224
  0x1EFC GAMMALUT3191 — Layer 3 palette/gamma correction memory region.
    fields as CORE.GAMMALUT224
  0x1F00 GAMMALUT3192 — Layer 3 palette/gamma correction memory region.
    fields as CORE.GAMMALUT224
  0x1F04 GAMMALUT3193 — Layer 3 palette/gamma correction memory region.
    fields as CORE.GAMMALUT224
  0x1F08 GAMMALUT3194 — Layer 3 palette/gamma correction memory region.
    fields as CORE.GAMMALUT224
  0x1F0C GAMMALUT3195 — Layer 3 palette/gamma correction memory region.
    fields as CORE.GAMMALUT224
  0x1F10 GAMMALUT3196 — Layer 3 palette/gamma correction memory region.
    fields as CORE.GAMMALUT224
  0x1F14 GAMMALUT3197 — Layer 3 palette/gamma correction memory region.
    fields as CORE.GAMMALUT224
  0x1F18 GAMMALUT3198 — Layer 3 palette/gamma correction memory region.
    fields as CORE.GAMMALUT224
  0x1F1C GAMMALUT3199 — Layer 3 palette/gamma correction memory region.
    fields as CORE.GAMMALUT224
  0x1F20 GAMMALUT3200 — Layer 3 palette/gamma correction memory region.
    fields as CORE.GAMMALUT224
  0x1F24 GAMMALUT3201 — Layer 3 palette/gamma correction memory region.
    fields as CORE.GAMMALUT224
  0x1F28 GAMMALUT3202 — Layer 3 palette/gamma correction memory region.
    fields as CORE.GAMMALUT224
  0x1F2C GAMMALUT3203 — Layer 3 palette/gamma correction memory region.
    fields as CORE.GAMMALUT224
  0x1F30 GAMMALUT3204 — Layer 3 palette/gamma correction memory region.
    fields as CORE.GAMMALUT224
  0x1F34 GAMMALUT3205 — Layer 3 palette/gamma correction memory region.
    fields as CORE.GAMMALUT224
  0x1F38 GAMMALUT3206 — Layer 3 palette/gamma correction memory region.
    fields as CORE.GAMMALUT224
  0x1F3C GAMMALUT3207 — Layer 3 palette/gamma correction memory region.
    fields as CORE.GAMMALUT224
  0x1F40 GAMMALUT3208 — Layer 3 palette/gamma correction memory region.
    fields as CORE.GAMMALUT224
  0x1F44 GAMMALUT3209 — Layer 3 palette/gamma correction memory region.
    fields as CORE.GAMMALUT224
  0x1F48 GAMMALUT3210 — Layer 3 palette/gamma correction memory region.
    fields as CORE.GAMMALUT224
  0x1F4C GAMMALUT3211 — Layer 3 palette/gamma correction memory region.
    fields as CORE.GAMMALUT224
  0x1F50 GAMMALUT3212 — Layer 3 palette/gamma correction memory region.
    fields as CORE.GAMMALUT224
  0x1F54 GAMMALUT3213 — Layer 3 palette/gamma correction memory region.
    fields as CORE.GAMMALUT224
  0x1F58 GAMMALUT3214 — Layer 3 palette/gamma correction memory region.
    fields as CORE.GAMMALUT224
  0x1F5C GAMMALUT3215 — Layer 3 palette/gamma correction memory region.
    fields as CORE.GAMMALUT224
  0x1F60 GAMMALUT3216 — Layer 3 palette/gamma correction memory region.
    fields as CORE.GAMMALUT224
  0x1F64 GAMMALUT3217 — Layer 3 palette/gamma correction memory region.
    fields as CORE.GAMMALUT224
  0x1F68 GAMMALUT3218 — Layer 3 palette/gamma correction memory region.
    fields as CORE.GAMMALUT224
  0x1F6C GAMMALUT3219 — Layer 3 palette/gamma correction memory region.
    fields as CORE.GAMMALUT224
  0x1F70 GAMMALUT3220 — Layer 3 palette/gamma correction memory region.
    fields as CORE.GAMMALUT224
  0x1F74 GAMMALUT3221 — Layer 3 palette/gamma correction memory region.
    fields as CORE.GAMMALUT224
  0x1F78 GAMMALUT3222 — Layer 3 palette/gamma correction memory region.
    fields as CORE.GAMMALUT224
  0x1F7C GAMMALUT3223 — Layer 3 palette/gamma correction memory region.
    fields as CORE.GAMMALUT224
  0x1F80 GAMMALUT3224 — Layer 3 palette/gamma correction memory region.
    fields as CORE.GAMMALUT224
  0x1F84 GAMMALUT3225 — Layer 3 palette/gamma correction memory region.
    fields as CORE.GAMMALUT224
  0x1F88 GAMMALUT3226 — Layer 3 palette/gamma correction memory region.
    fields as CORE.GAMMALUT224
  0x1F8C GAMMALUT3227 — Layer 3 palette/gamma correction memory region.
    fields as CORE.GAMMALUT224
  0x1F90 GAMMALUT3228 — Layer 3 palette/gamma correction memory region.
    fields as CORE.GAMMALUT224
  0x1F94 GAMMALUT3229 — Layer 3 palette/gamma correction memory region.
    fields as CORE.GAMMALUT224
  0x1F98 GAMMALUT3230 — Layer 3 palette/gamma correction memory region.
    fields as CORE.GAMMALUT224
  0x1F9C GAMMALUT3231 — Layer 3 palette/gamma correction memory region.
    fields as CORE.GAMMALUT224
  0x1FA0 GAMMALUT3232 — Layer 3 palette/gamma correction memory region.
    fields as CORE.GAMMALUT224
  0x1FA4 GAMMALUT3233 — Layer 3 palette/gamma correction memory region.
    fields as CORE.GAMMALUT224
  0x1FA8 GAMMALUT3234 — Layer 3 palette/gamma correction memory region.
    fields as CORE.GAMMALUT224
  0x1FAC GAMMALUT3235 — Layer 3 palette/gamma correction memory region.
    fields as CORE.GAMMALUT224
  0x1FB0 GAMMALUT3236 — Layer 3 palette/gamma correction memory region.
    fields as CORE.GAMMALUT224
  0x1FB4 GAMMALUT3237 — Layer 3 palette/gamma correction memory region.
    fields as CORE.GAMMALUT224
  0x1FB8 GAMMALUT3238 — Layer 3 palette/gamma correction memory region.
    fields as CORE.GAMMALUT224
  0x1FBC GAMMALUT3239 — Layer 3 palette/gamma correction memory region.
    fields as CORE.GAMMALUT224
  0x1FC0 GAMMALUT3240 — Layer 3 palette/gamma correction memory region.
    fields as CORE.GAMMALUT224
  0x1FC4 GAMMALUT3241 — Layer 3 palette/gamma correction memory region.
    fields as CORE.GAMMALUT224
  0x1FC8 GAMMALUT3242 — Layer 3 palette/gamma correction memory region.
    fields as CORE.GAMMALUT224
  0x1FCC GAMMALUT3243 — Layer 3 palette/gamma correction memory region.
    fields as CORE.GAMMALUT224
  0x1FD0 GAMMALUT3244 — Layer 3 palette/gamma correction memory region.
    fields as CORE.GAMMALUT224
  0x1FD4 GAMMALUT3245 — Layer 3 palette/gamma correction memory region.
    fields as CORE.GAMMALUT224
  0x1FD8 GAMMALUT3246 — Layer 3 palette/gamma correction memory region.
    fields as CORE.GAMMALUT224
  0x1FDC GAMMALUT3247 — Layer 3 palette/gamma correction memory region.
    fields as CORE.GAMMALUT224
  0x1FE0 GAMMALUT3248 — Layer 3 palette/gamma correction memory region.
    fields as CORE.GAMMALUT224
  0x1FE4 GAMMALUT3249 — Layer 3 palette/gamma correction memory region.
    fields as CORE.GAMMALUT224
  0x1FE8 GAMMALUT3250 — Layer 3 palette/gamma correction memory region.
    fields as CORE.GAMMALUT224
  0x1FEC GAMMALUT3251 — Layer 3 palette/gamma correction memory region.
    fields as CORE.GAMMALUT224
  0x1FF0 GAMMALUT3252 — Layer 3 palette/gamma correction memory region.
    fields as CORE.GAMMALUT224
  0x1FF4 GAMMALUT3253 — Layer 3 palette/gamma correction memory region.
    fields as CORE.GAMMALUT224
  0x1FF8 GAMMALUT3254 — Layer 3 palette/gamma correction memory region.
    fields as CORE.GAMMALUT224
  0x1FFC GAMMALUT3255 — Layer 3 palette/gamma correction memory region.
    fields as CORE.GAMMALUT224
